# N569S register map
File version: 1.0
N569S SVD file
Registers are 32-bit, read-write, reset 0x0 unless marked. A register's access mark holds for its fields unless they carry their own. Offsets are from the block's base; lines under a group give offsets from that group; [hi:lo] are bit positions; {n}, {i} and the like mark numbered series; 'fields as' and 'values as' point back to an identical list; <NAME> marks a mode.

## Memory map
0x40004000 WDT size 0x4 — WDT Register Map
0x40008000 RTC size 0x4 — RTC Register Map
0x40010000 TMR blocks up to offset 0x50 — TMR Register Map
0x40030000 SPI0 blocks up to offset 0x3C — SPI Register Map
0x40060000 UART0 size 0x28 — UART0 Register Map
0x40070000 DPWM size 0x14 — DPWM Register Map
0x50000000 SYS blocks up to offset 0x11C — SYS Register Map
0x50000300 INT blocks up to offset 0x88 — INT Register Map
0x50004000 GPIO blocks up to offset 0x858 — GPIO Register Map
0x50007000 SPIM blocks up to offset 0x30 — SPIM Register Map
0x50009000 PDMA_CH0 size 0x28 — PDMA Register Map
0x50009100 PDMA_CH1 size 0x28 — PDMA Register Map
0x50009F00 PDMA_GCR blocks up to offset 0x10 — PDMA Register Map
0x5000C000 FMC size 0x18 — FCM Register Map
0xE000E000 SCS blocks up to offset 0x414 — SCS Register Map

## SCS — SCS Register Map
Base 0xE000E000
0x100 NVIC_ISER — IRQ0 ~ IRQ18 Set-enable Control Register
  [15:0] SETENA — Interrupt Set-Enable Bit. The NVIC_ISER register enables interrupts, and shows what interrupts are enabled. Each bit represents an interrupt number from IRQ0 ~ IRQ18 (Vector number from 16 ~ 34). . Write Operation:
    0=No effect. Interrupt Disabled; 1=Interrupt Enabled
0x180 NVIC_ICER — IRQ0 ~ IRQ18 Clear-enable Control Register
  [15:0] CLRENA — Interrupt Clear-Enable Bit. The NVIC_ICER register disables interrupts, and shows what interrupts are enabled. Each bit represents an interrupt number from IRQ0 ~ IRQ18 (Vector number from 16 ~ 34). . Write Operation:
    0=No effect. Interrupt Disabled; 1=Interrupt Disabled. Interrupt Enabled
0x200 NVIC_ISPR — IRQ0 ~ IRQ18 Set-pending Control Register
  [15:0] SETPEND — Interrupt Set-Pending Bit. The NVIC_ISPR register forces interrupts into the pending state, and shows what interrupts are pending. Each bit represents an interrupt number from IRQ0 ~ IRQ18 (Vector number from 16 ~ 34). . Write Operation:
    0=No effect. Interrupt is not pending; 1=Changes interrupt state to pending. Interrupt is pending
0x280 NVIC_ICPR — IRQ0 ~ IRQ18 Clear-pending Control Register
  [15:0] CLRPEND — Interrupt Clear-Pending Bit. The NVIC_ICPR register removes the pending state of associated interrupts, and shows what interrupts are pending. Each bit represents an interrupt number from IRQ0 ~ IRQ18 (Vector number from 16 ~ 34). Write Operation:
    0=No effect. Interrupt is not pending; 1=Removes pending state of an interrupt. Interrupt is pending
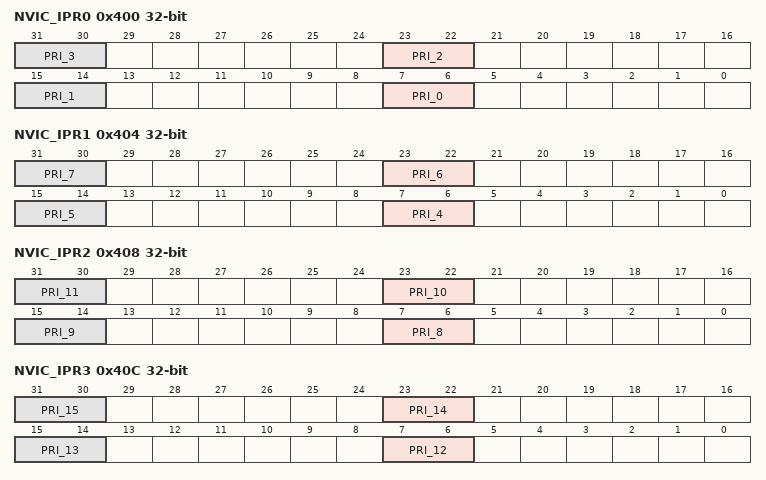
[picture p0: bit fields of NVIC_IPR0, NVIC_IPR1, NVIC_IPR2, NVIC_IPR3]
0x400 NVIC_IPR0 — IRQ0 ~ IRQ3 Priority Control Register
  [8n+7:8n+6] PRI_{n} (n=0..3) — Priority Of IRQ{n} "0" denotes the highest priority and "3" denotes lowest priority
0x404 NVIC_IPR1 — IRQ4 ~ IRQ7 Priority Control Register
  [8n-25:8n-26] PRI_{n} (n=4..7) — Priority Of IRQ{n} "0" denotes the highest priority and "3" denotes lowest priority
0x408 NVIC_IPR2 — IRQ8 ~ IRQ11 Priority Control Register
  [8n-57:8n-58] PRI_{n} (n=8..11) — Priority Of IRQ{n} "0" denotes the highest priority and "3" denotes lowest priority
0x40C NVIC_IPR3 — IRQ12 ~ IRQ15 Priority Control Register
  [8n-89:8n-90] PRI_{n} (n=12..15) — Priority Of IRQ{n} "0" denotes the highest priority and "3" denotes lowest priority
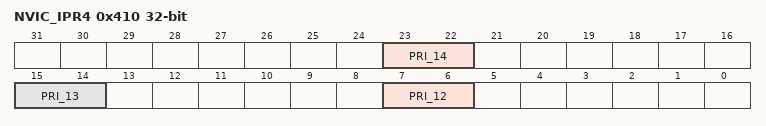
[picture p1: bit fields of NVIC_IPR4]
0x410 NVIC_IPR4 — IRQ16 ~ IRQ18 Priority Control Register
  [23:22] PRI_14 — Priority Of IRQ14 "0" denotes the highest priority and "3" denotes lowest priority
  [15:14] PRI_13 — Priority Of IRQ13 "0" denotes the highest priority and "3" denotes lowest priority
  [7:6] PRI_12 — Priority Of IRQ12 "0" denotes the highest priority and "3" denotes lowest priority

## INT — INT Register Map
Base 0x50000300
0x00 IRQ0_SRC ro reset not defined — IRQ0 (WDT) Interrupt Source Identity Register
  [2:0] INT_SRC — Interrupt Source Identity. Bit2: 0. Bit1: 0. Bit0: WDT_INT
0x04 IRQ1_SRC ro reset not defined — IRQ1 (DPWM) Interrupt Source Identity Register
  [2:0] INT_SRC — Interrupt Source Identity. Bit2: 0. Bit1: 0. Bit0: DPWM_INT
0x0C IRQ3_SRC ro reset not defined — Reserved
0x10 IRQ4_SRC ro reset not defined — IRQ4 (SPIM) Interrupt Source Identity Register
  [2:0] INT_SRC — Interrupt Source Identity. Bit2: 0. Bit1: 0. Bit0: SPIM_INT
{0x0+4i} IRQ{i}_SRC ro reset not defined (i=5..7) — IRQ{i} (Timer{i-5}) Interrupt Source Identity Register
  [2:0] INT_SRC — Interrupt Source Identity. Bit2: 0. Bit1: 0. Bit0: Timer{i-5}_INT
0x20 IRQ8_SRC ro reset not defined — IRQ8 (GPA/B) Interrupt Source Identity Register
  [2:0] INT_SRC — Interrupt Source Identity. Bit2: 0. Bit1: GPB_INT. Bit0: GPA_INT
0x24 IRQ9_SRC ro reset not defined — IRQ9 (SPI0) Interrupt Source Identity Register
  [2:0] INT_SRC — Interrupt Source Identity. Bit2: 0. Bit1: 0. Bit0: SPI0_INT
0x28 IRQ10_SRC ro reset not defined — IRQ10 (PWM0) Interrupt Source Identity Register
  [2:0] INT_SRC — Interrupt Source Identity. Bit2: 0. Bit1: 0. Bit0: PWM0_INT
0x2C IRQ11_SRC ro reset not defined — IRQ11 (PDMA) Interrupt Source Identity Register
  [2:0] INT_SRC — Interrupt Source Identity. Bit2: 0. Bit1: 0. Bit0: PDMA_INT
0x30 IRQ12_SRC ro reset not defined — IRQ12 (TimerF) Interrupt Source Identity Register
  [2:0] INT_SRC — Interrupt Source Identity. Bit2: 0. Bit1: 0. Bit0: TimerF_INT
0x34 IRQ13_SRC ro reset not defined — IRQ13 (RTC) Interrupt Source Identity Register
  [2:0] INT_SRC — Interrupt Source Identity. Bit2: 0. Bit1: 0. Bit0: RTC_INT
0x38 IRQ14_SRC ro reset not defined — Reserved
0x3C IRQ15_SRC ro reset not defined — IRQ15 (PWM1) Interrupt Source Identity Register
  [2:0] INT_SRC — Interrupt Source Identity. Bit2: 0. Bit1: 0. Bit0: UART0_INT
0x40 IRQ16_SRC ro reset not defined — Reserved
0x44 IRQ17_SRC ro reset not defined — IRQ17 (UART) Interrupt Source Identity Register
0x48 IRQ18_SRC ro reset not defined — IRQ18 (BOD) Interrupt Source Identity Register
  [2:0] INT_SRC — Interrupt Source Identity. Bit2: 0. Bit1: 0. Bit0: BOD_INT
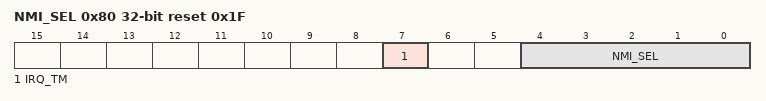
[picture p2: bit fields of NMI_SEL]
0x80 NMI_SEL reset 0x1F — NMI Source Interrupt Select Control Register
  [7] IRQ_TM — IRQ Test Mode. This bit is the protected bit. To program this bit needs an open lock sequence, write "59h", "16h", "88h" to register SYS_REGLCTL to un-lock this bit. Refer to the register SYS_REGLCTL at address SYS_BA+0x100.
    0=The interrupt register MCU_IRQ operates in normal mode. The MCU_IRQ collects all the interrupts from the peripheral and generates interrupt to MCU; 1=All the interrupts from peripheral to MCU are blocked. The peripheral IRQ signals (0-15) are replaced by the value in the MCU_IRQ register
  [4:0] NMI_SEL — NMI Source Interrupt Select. The NMI interrupt to Cortex-M0 can be selected from one of the interrupt [18:0]. The NMI_SEL bit is used to select the NMI interrupt source. Note: IRQ3, IRQ14 and IRQ16 are reserved.
0x84 MCU_IRQ — MCU IRQ Number Identify Register
  [15:0] MCU_IRQ — MCU IRQ Source Test Mode. The MCU_IRQ collects all the interrupts from the peripherals and generates the synchronous interrupt to MCU Cortex-M0. There are two modes to generate interrupt to MCU Cortex-M0, the normal mode and test mode. When MCU_IRQ[n] is "0": Writing MCU_IRQ[n] "1" will generate an interrupt to Cortex_M0 IRQ[n]. When MCU_IRQ[n] is "1" (meaning an interrupt is asserted): Writing MCU_IRQ[n] "1" will clear the interrupt; writing MCU_IRQ[n] "0": has no effect. Note: IRQ3, IRQ14 and IRQ16 are reserved.
